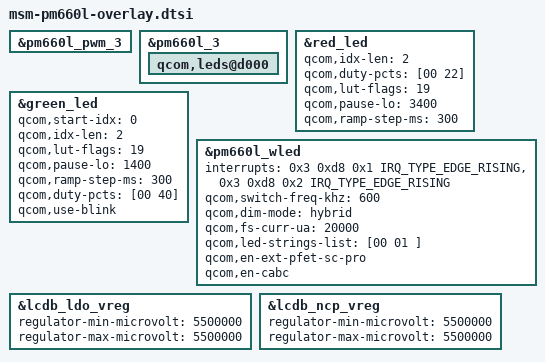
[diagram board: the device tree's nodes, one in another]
/* SPDX-License-Identifier: GPL-2.0 */

&pm660l_pwm_3 {
	/delete-property/ qcom,period;
	/delete-node/ qcom,lpg;
};

&pm660l_3 {
	qcom,leds@d000 {
		/delete-node/ qcom,rgb_2;
	};
};

&red_led {
	qcom,idx-len = <2>;
	qcom,duty-pcts = [00 22];
	qcom,lut-flags = <19>;
	qcom,pause-lo = <3400>;
	qcom,ramp-step-ms = <300>;
};

&green_led {
	qcom,start-idx = <0>;
	qcom,idx-len = <2>;
	qcom,lut-flags = <19>;
	qcom,pause-lo = <1400>;
	qcom,ramp-step-ms = <300>;
	qcom,duty-pcts = [00 40];
	qcom,use-blink;
};

&pm660l_wled {
	interrupts = <0x3 0xd8 0x1 IRQ_TYPE_EDGE_RISING>,
				 <0x3 0xd8 0x2 IRQ_TYPE_EDGE_RISING>;
	interrupt-names = "ovp-irq", "sc-irq";
	qcom,switch-freq-khz = <600>;
	qcom,dim-mode = "hybrid";
	qcom,fs-curr-ua = <20000>;
	qcom,led-strings-list = [00 01/* 02*/];
	qcom,en-ext-pfet-sc-pro;
	qcom,en-cabc;
};

&lcdb_ldo_vreg {
	regulator-min-microvolt = <5500000>;
	regulator-max-microvolt = <5500000>;
};

&lcdb_ncp_vreg {
	regulator-min-microvolt = <5500000>;
	regulator-max-microvolt = <5500000>;
};
